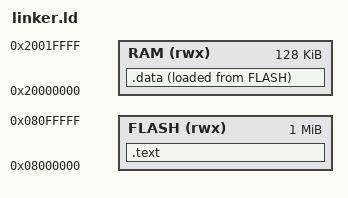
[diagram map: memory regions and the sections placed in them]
/* linker.ld */
MEMORY
{
    /* write set for ease of use */
    FLASH (rwx) : ORIGIN = 0x08000000, LENGTH = 1024K
    RAM  (rwx) : ORIGIN = 0x20000000, LENGTH = 128K
}

SECTIONS
{
    .text :
    {
        KEEP(*(.isr_vector))
        *(.text*)
        *(.rodata*)
    } > FLASH

    .data :
    {
        . = ALIGN(4);
        _sdata = .;
        *(.data*)
        . = ALIGN(4);
        _edata = .;
    } > RAM AT > FLASH

    _sidata = LOADADDR(.data);
}
